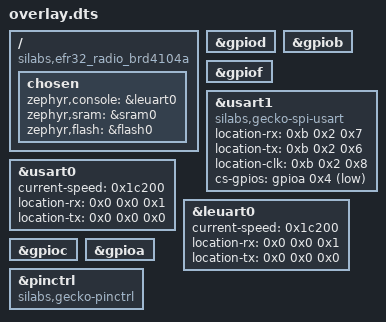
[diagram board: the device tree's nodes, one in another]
/ {
	compatible = "silabs,efr32_radio_brd4104a", "silabs,efr32bg13p";
	chosen {
		zephyr,console = &leuart0;
		zephyr,sram = &sram0;
		zephyr,flash = &flash0;
	};
};
&gpiod{
	status = "okay";
};
&gpiob{
	status = "okay";
};
&gpiof{
	status = "okay";
};
&usart1{
	compatible = "silabs,gecko-spi-usart";
	status = "okay";
	#address-cells = < 0x1 >;
	#size-cells = < 0x0 >;
	location-rx = < 0xb 0x2 0x7 >;
	location-tx = < 0xb 0x2 0x6 >;
	location-clk = < 0xb 0x2 0x8 >;
	cs-gpios = < &gpioa 0x4 0x1 >;
};
&usart0{
	status = "okay";
	current-speed = < 0x1c200 >;
	location-rx = < 0x0 0x0 0x1 >;
	location-tx = < 0x0 0x0 0x0 >;
};
&leuart0{
	status = "okay";
	current-speed = < 0x1c200 >;
	location-rx = < 0x0 0x0 0x1 >;
	location-tx = < 0x0 0x0 0x0 >;
};
&gpioc{
	status = "okay";
};
&gpioa{
	status = "okay";
};
&pinctrl{
	compatible = "silabs,gecko-pinctrl";
};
